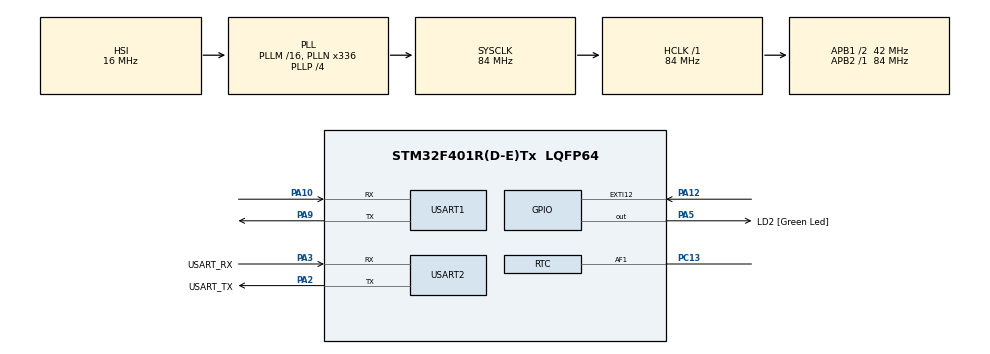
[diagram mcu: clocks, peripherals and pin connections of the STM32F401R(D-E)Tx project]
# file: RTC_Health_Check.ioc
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Mcu.Family=STM32F4
Mcu.Name=STM32F401R(D-E)Tx
Mcu.Package=LQFP64
NVIC.PriorityGroup=NVIC_PRIORITYGROUP_0
PA10.Mode=Asynchronous
PA10.Signal=USART1_RX
PA12.Signal=GPXTI12
PA13.GPIO_Label=TMS
PA13.Mode=Serial_Wire
PA13.Signal=SYS_JTMS-SWDIO
PA14.GPIO_Label=TCK
PA14.Mode=Serial_Wire
PA14.Signal=SYS_JTCK-SWCLK
PA2.GPIO_Label=USART_TX
PA2.GPIO_Mode=GPIO_MODE_AF_PP
PA2.GPIO_PuPd=GPIO_NOPULL
PA2.GPIO_Speed=GPIO_SPEED_FREQ_LOW
PA2.Mode=Asynchronous
PA2.Signal=USART2_TX
PA3.GPIO_Label=USART_RX
PA3.GPIO_Mode=GPIO_MODE_AF_PP
PA3.GPIO_PuPd=GPIO_NOPULL
PA3.GPIO_Speed=GPIO_SPEED_FREQ_LOW
PA3.Mode=Asynchronous
PA3.Signal=USART2_RX
PA5.GPIO_Label=LD2 [Green Led]
PA5.GPIO_Mode=GPIO_MODE_OUTPUT_PP
PA5.GPIO_PuPd=GPIO_NOPULL
PA5.GPIO_Speed=GPIO_SPEED_FREQ_LOW
PA5.Signal=GPIO_Output
PA9.Mode=Asynchronous
PA9.Signal=USART1_TX
PB3.GPIO_Label=SWO
PB3.Signal=SYS_JTDO-SWO
PC13-ANTI_TAMP.Mode=Timestamp enabled - Input Enabled to AF1
PC13-ANTI_TAMP.Signal=RTC_AF1
PC14-OSC32_IN.Mode=LSE-External-Oscillator
PC14-OSC32_IN.Signal=RCC_OSC32_IN
PC15-OSC32_OUT.Mode=LSE-External-Oscillator
PC15-OSC32_OUT.Signal=RCC_OSC32_OUT
PH0\ -\ OSC_IN.Mode=HSE-External-Clock-Source
PH0\ -\ OSC_IN.Signal=RCC_OSC_IN
PH1\ -\ OSC_OUT.Mode=HSE-External-Clock-Source
PH1\ -\ OSC_OUT.Signal=RCC_OSC_OUT
ProjectManager.HeapSize=0x200
ProjectManager.StackSize=0x400
ProjectManager.TargetToolchain=SW4STM32
RCC.48MHZClocksFreq_Value=48000000
RCC.AHBFreq_Value=84000000
RCC.APB1CLKDivider=RCC_HCLK_DIV2
RCC.APB1Freq_Value=42000000
RCC.APB1TimFreq_Value=84000000
RCC.APB2Freq_Value=84000000
RCC.APB2TimFreq_Value=84000000
RCC.CortexFreq_Value=84000000
RCC.HCLKFreq_Value=84000000
RCC.HSE_VALUE=8000000
RCC.HSI_VALUE=16000000
RCC.PLLN=336
RCC.PLLP=RCC_PLLP_DIV4
RCC.PLLQ=7
RCC.SYSCLKFreq_VALUE=84000000
RCC.SYSCLKSource=RCC_SYSCLKSOURCE_PLLCLK
RCC.VCOOutputFreq_Value=336000000
RTC.TimeStampPin=RTC_TIMESTAMPPIN_DEFAULT
USART1.VirtualMode=VM_ASYNC
USART2.VirtualMode=VM_ASYNC
VP_RTC_VS_RTC_Activate.Mode=RTC_Enabled
VP_RTC_VS_RTC_Calendar.Mode=RTC_Calendar
board=NUCLEO-F401RE

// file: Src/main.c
/**
  ******************************************************************************
  * @file           : main.c
  * @brief          : Main program body
  ******************************************************************************
  ** This notice applies to any and all portions of this file
  * that are not between comment pairs USER CODE BEGIN and
  * USER CODE END. Other portions of this file, whether
  * inserted by the user or by software development tools
  * are owned by their respective copyright owners.
  *
  * COPYRIGHT(c) 2019 STMicroelectronics
  *
  * Redistribution and use in source and binary forms, with or without modification,
  * are permitted provided that the following conditions are met:
  *   1. Redistributions of source code must retain the above copyright notice,
  *      this list of conditions and the following disclaimer.
  *   2. Redistributions in binary form must reproduce the above copyright notice,
  *      this list of conditions and the following disclaimer in the documentation
  *      and/or other materials provided with the distribution.
  *   3. Neither the name of STMicroelectronics nor the names of its contributors
  *      may be used to endorse or promote products derived from this software
  *      without specific prior written permission.
  *
  * THIS SOFTWARE IS PROVIDED BY THE COPYRIGHT HOLDERS AND CONTRIBUTORS "AS IS"
  * AND ANY EXPRESS OR IMPLIED WARRANTIES, INCLUDING, BUT NOT LIMITED TO, THE
  * IMPLIED WARRANTIES OF MERCHANTABILITY AND FITNESS FOR A PARTICULAR PURPOSE ARE
  * DISCLAIMED. IN NO EVENT SHALL THE COPYRIGHT HOLDER OR CONTRIBUTORS BE LIABLE
  * FOR ANY DIRECT, INDIRECT, INCIDENTAL, SPECIAL, EXEMPLARY, OR CONSEQUENTIAL
  * DAMAGES (INCLUDING, BUT NOT LIMITED TO, PROCUREMENT OF SUBSTITUTE GOODS OR
  * SERVICES; LOSS OF USE, DATA, OR PROFITS; OR BUSINESS INTERRUPTION) HOWEVER
  * CAUSED AND ON ANY THEORY OF LIABILITY, WHETHER IN CONTRACT, STRICT LIABILITY,
  * OR TORT (INCLUDING NEGLIGENCE OR OTHERWISE) ARISING IN ANY WAY OUT OF THE USE
  * OF THIS SOFTWARE, EVEN IF ADVISED OF THE POSSIBILITY OF SUCH DAMAGE.
  *
  ******************************************************************************
  */
#include "main.h"
#include "stm32f4xx_hal.h"

/* USER CODE BEGIN Includes */
#include "rtc_health_check.h"
/* USER CODE END Includes */

RTC_HandleTypeDef hrtc;

UART_HandleTypeDef huart1;
UART_HandleTypeDef huart2;

/* USER CODE BEGIN PV */
/* Private variables ---------------------------------------------------------*/

/* USER CODE END PV */

void SystemClock_Config(void);
static void MX_GPIO_Init(void);
static void MX_USART2_UART_Init(void);
static void MX_USART1_UART_Init(void);
static void MX_RTC_Init(void);

/* USER CODE BEGIN PFP */
/* Private function prototypes -----------------------------------------------*/

/* USER CODE END PFP */

int main(void)
{

  /* MCU Configuration----------------------------------------------------------*/

  /* Reset of all peripherals, Initializes the Flash interface and the Systick. */
  HAL_Init();

  /* Configure the system clock */
  SystemClock_Config();

  /* Initialize all configured peripherals */
  MX_GPIO_Init();
  MX_USART2_UART_Init();
  MX_USART1_UART_Init();
  MX_RTC_Init();

  /* Infinite loop */
  while (1)
  {

  }

}

void SystemClock_Config(void)
{

  RCC_OscInitTypeDef RCC_OscInitStruct;
  RCC_ClkInitTypeDef RCC_ClkInitStruct;
  RCC_PeriphCLKInitTypeDef PeriphClkInitStruct;

    /**Configure the main internal regulator output voltage
    */
  __HAL_RCC_PWR_CLK_ENABLE();

  __HAL_PWR_VOLTAGESCALING_CONFIG(PWR_REGULATOR_VOLTAGE_SCALE2);

    /**Initializes the CPU, AHB and APB busses clocks
    */
  RCC_OscInitStruct.OscillatorType = RCC_OSCILLATORTYPE_HSI|RCC_OSCILLATORTYPE_LSI;
  RCC_OscInitStruct.HSIState = RCC_HSI_ON;
  RCC_OscInitStruct.HSICalibrationValue = 16;
  RCC_OscInitStruct.LSIState = RCC_LSI_ON;
  RCC_OscInitStruct.PLL.PLLState = RCC_PLL_ON;
  RCC_OscInitStruct.PLL.PLLSource = RCC_PLLSOURCE_HSI;
  RCC_OscInitStruct.PLL.PLLM = 16;
  RCC_OscInitStruct.PLL.PLLN = 336;
  RCC_OscInitStruct.PLL.PLLP = RCC_PLLP_DIV4;
  RCC_OscInitStruct.PLL.PLLQ = 7;
  if (HAL_RCC_OscConfig(&RCC_OscInitStruct) != HAL_OK)
  {
    _Error_Handler(__FILE__, __LINE__);
  }

    /**Initializes the CPU, AHB and APB busses clocks
    */
  RCC_ClkInitStruct.ClockType = RCC_CLOCKTYPE_HCLK|RCC_CLOCKTYPE_SYSCLK
                              |RCC_CLOCKTYPE_PCLK1|RCC_CLOCKTYPE_PCLK2;
  RCC_ClkInitStruct.SYSCLKSource = RCC_SYSCLKSOURCE_PLLCLK;
  RCC_ClkInitStruct.AHBCLKDivider = RCC_SYSCLK_DIV1;
  RCC_ClkInitStruct.APB1CLKDivider = RCC_HCLK_DIV2;
  RCC_ClkInitStruct.APB2CLKDivider = RCC_HCLK_DIV1;

  if (HAL_RCC_ClockConfig(&RCC_ClkInitStruct, FLASH_LATENCY_2) != HAL_OK)
  {
    _Error_Handler(__FILE__, __LINE__);
  }

  PeriphClkInitStruct.PeriphClockSelection = RCC_PERIPHCLK_RTC;
  PeriphClkInitStruct.RTCClockSelection = RCC_RTCCLKSOURCE_LSI;
  if (HAL_RCCEx_PeriphCLKConfig(&PeriphClkInitStruct) != HAL_OK)
  {
    _Error_Handler(__FILE__, __LINE__);
  }

    /**Configure the Systick interrupt time
    */
  HAL_SYSTICK_Config(HAL_RCC_GetHCLKFreq()/1000);

    /**Configure the Systick
    */
  HAL_SYSTICK_CLKSourceConfig(SYSTICK_CLKSOURCE_HCLK);

  /* SysTick_IRQn interrupt configuration */
  HAL_NVIC_SetPriority(SysTick_IRQn, 0, 0);
}

/* RTC init function */
static void MX_RTC_Init(void)
{

  RTC_TimeTypeDef sTime;
  RTC_DateTypeDef sDate;

    /**Initialize RTC Only
    */
  hrtc.Instance = RTC;
  hrtc.Init.HourFormat = RTC_HOURFORMAT_24;
  hrtc.Init.AsynchPrediv = 127;
  hrtc.Init.SynchPrediv = 255;
  hrtc.Init.OutPut = RTC_OUTPUT_DISABLE;
  hrtc.Init.OutPutPolarity = RTC_OUTPUT_POLARITY_HIGH;
  hrtc.Init.OutPutType = RTC_OUTPUT_TYPE_OPENDRAIN;
  if (HAL_RTC_Init(&hrtc) != HAL_OK)
  {
    _Error_Handler(__FILE__, __LINE__);
  }

    /**Initialize RTC and set the Time and Date
    */
  sTime.Hours = 0x0;
  sTime.Minutes = 0x0;
  sTime.Seconds = 0x0;
  sTime.DayLightSaving = RTC_DAYLIGHTSAVING_NONE;
  sTime.StoreOperation = RTC_STOREOPERATION_RESET;
  if (HAL_RTC_SetTime(&hrtc, &sTime, RTC_FORMAT_BCD) != HAL_OK)
  {
    _Error_Handler(__FILE__, __LINE__);
  }

  sDate.WeekDay = RTC_WEEKDAY_MONDAY;
  sDate.Month = RTC_MONTH_JANUARY;
  sDate.Date = 0x1;
  sDate.Year = 0x0;

  if (HAL_RTC_SetDate(&hrtc, &sDate, RTC_FORMAT_BCD) != HAL_OK)
  {
    _Error_Handler(__FILE__, __LINE__);
  }

    /**Enable the TimeStamp
    */
  if (HAL_RTCEx_SetTimeStamp(&hrtc, RTC_TIMESTAMPEDGE_RISING, RTC_TIMESTAMPPIN_DEFAULT) != HAL_OK)
  {
    _Error_Handler(__FILE__, __LINE__);
  }

}

/* USART1 init function */
static void MX_USART1_UART_Init(void)
{

  huart1.Instance = USART1;
  huart1.Init.BaudRate = 115200;
  huart1.Init.WordLength = UART_WORDLENGTH_8B;
  huart1.Init.StopBits = UART_STOPBITS_1;
  huart1.Init.Parity = UART_PARITY_NONE;
  huart1.Init.Mode = UART_MODE_TX_RX;
  huart1.Init.HwFlowCtl = UART_HWCONTROL_NONE;
  huart1.Init.OverSampling = UART_OVERSAMPLING_16;
  if (HAL_UART_Init(&huart1) != HAL_OK)
  {
    _Error_Handler(__FILE__, __LINE__);
  }

}

/* USART2 init function */
static void MX_USART2_UART_Init(void)
{

  huart2.Instance = USART2;
  huart2.Init.BaudRate = 115200;
  huart2.Init.WordLength = UART_WORDLENGTH_8B;
  huart2.Init.StopBits = UART_STOPBITS_1;
  huart2.Init.Parity = UART_PARITY_NONE;
  huart2.Init.Mode = UART_MODE_TX_RX;
  huart2.Init.HwFlowCtl = UART_HWCONTROL_NONE;
  huart2.Init.OverSampling = UART_OVERSAMPLING_16;
  if (HAL_UART_Init(&huart2) != HAL_OK)
  {
    _Error_Handler(__FILE__, __LINE__);
  }

}

/** Configure pins as
        * Analog
        * Input
        * Output
        * EVENT_OUT
        * EXTI
*/
static void MX_GPIO_Init(void)
{

  GPIO_InitTypeDef GPIO_InitStruct;

  /* GPIO Ports Clock Enable */
  __HAL_RCC_GPIOC_CLK_ENABLE();
  __HAL_RCC_GPIOH_CLK_ENABLE();
  __HAL_RCC_GPIOA_CLK_ENABLE();
  __HAL_RCC_GPIOB_CLK_ENABLE();

  /*Configure GPIO pin Output Level */
  HAL_GPIO_WritePin(LD2_GPIO_Port, LD2_Pin, GPIO_PIN_RESET);

  /*Configure GPIO pin : LD2_Pin */
  GPIO_InitStruct.Pin = LD2_Pin;
  GPIO_InitStruct.Mode = GPIO_MODE_OUTPUT_PP;
  GPIO_InitStruct.Pull = GPIO_NOPULL;
  GPIO_InitStruct.Speed = GPIO_SPEED_FREQ_LOW;
  HAL_GPIO_Init(LD2_GPIO_Port, &GPIO_InitStruct);

  /*Configure GPIO pin : PA12 */
  GPIO_InitStruct.Pin = GPIO_PIN_12;
  GPIO_InitStruct.Mode = GPIO_MODE_IT_RISING;
  GPIO_InitStruct.Pull = GPIO_NOPULL;
  HAL_GPIO_Init(GPIOA, &GPIO_InitStruct);

}

void _Error_Handler(char *file, int line)
{
  while(1)
  {
  }
}

/************************ (C) COPYRIGHT STMicroelectronics *****END OF FILE****/
